# ICSSM_ICSSM_PR1_IEP0_SLV_4802E000h register map
Vendor: Texas Instruments
Peripheral module from a debugger description file (folder AM261x).
Registers are 32-bit, read-write, reset 0x0 unless marked. A register's access mark holds for its fields unless they carry their own. Offsets are as the file gives them; lines under a group give offsets from that group; [hi:lo] are bit positions; {n}, {i} and the like mark numbered series; 'fields as' and 'values as' point back to an identical list; <NAME> marks a mode.

## ICSSM_PR1_IEP0_SLV
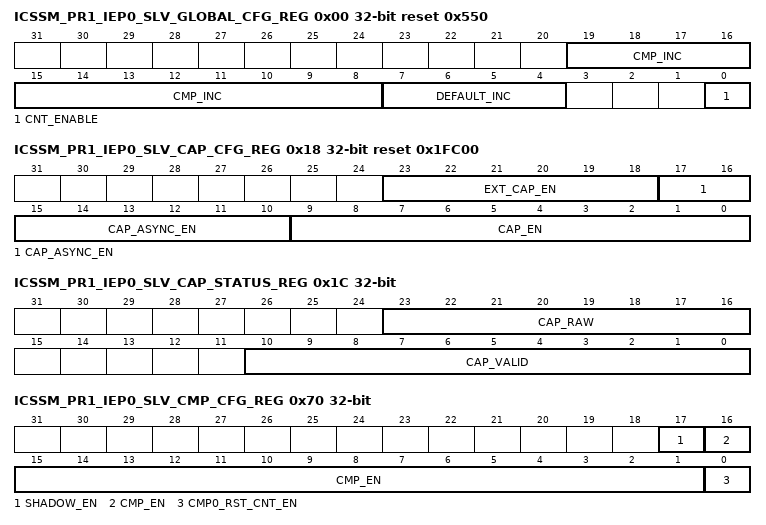
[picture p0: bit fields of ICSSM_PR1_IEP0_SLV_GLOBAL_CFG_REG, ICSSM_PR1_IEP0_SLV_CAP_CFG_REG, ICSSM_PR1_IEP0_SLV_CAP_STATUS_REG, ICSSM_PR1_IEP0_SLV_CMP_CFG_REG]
0x00 ICSSM_PR1_IEP0_SLV_GLOBAL_CFG_REG reset 0x550
  [19:8] CMP_INC, [7:4] DEFAULT_INC, [0] CNT_ENABLE
0x04 ICSSM_PR1_IEP0_SLV_GLOBAL_STATUS_REG access not given
  [0] CNT_OVF — (access R/W1TC)
0x08 ICSSM_PR1_IEP0_SLV_COMPEN_REG
  [22:0] COMPEN_CNT
0x0C ICSSM_PR1_IEP0_SLV_SLOW_COMPEN_REG
  [31:0] SLOW_COMPEN_CNT
0x10 ICSSM_PR1_IEP0_SLV_COUNT_REG0
  [31:0] COUNT_LO
0x14 ICSSM_PR1_IEP0_SLV_COUNT_REG1
  [31:0] COUNT_HI
0x18 ICSSM_PR1_IEP0_SLV_CAP_CFG_REG reset 0x1FC00
  [23:18] EXT_CAP_EN, [17:10] CAP_ASYNC_EN, [9:0] CAP_EN
0x1C ICSSM_PR1_IEP0_SLV_CAP_STATUS_REG ro
  [23:16] CAP_RAW, [10:0] CAP_VALID
{0x20+8i} ICSSM_PR1_IEP0_SLV_CAPR{i}_REG0 ro (i=0..6)
  [31:0] CAPR{i}_0
{0x24+8i} ICSSM_PR1_IEP0_SLV_CAPR{i}_REG1 ro (i=0..6)
  [31:0] CAPR{i}_1
0x58 ICSSM_PR1_IEP0_SLV_CAPF6_REG0 ro
  [31:0] CAPF6_0
0x5C ICSSM_PR1_IEP0_SLV_CAPF6_REG1 ro
  [31:0] CAPF6_1
0x60 ICSSM_PR1_IEP0_SLV_CAPR7_REG0 ro
  [31:0] CAPR7_0
0x64 ICSSM_PR1_IEP0_SLV_CAPR7_REG1 ro
  [31:0] CAPR7_1
0x68 ICSSM_PR1_IEP0_SLV_CAPF7_REG0 ro
  [31:0] CAPF7_0
0x6C ICSSM_PR1_IEP0_SLV_CAPF7_REG1 ro
  [31:0] CAPF7_1
0x70 ICSSM_PR1_IEP0_SLV_CMP_CFG_REG
  [17] SHADOW_EN, [16:1] CMP_EN, [0] CMP0_RST_CNT_EN
0x74 ICSSM_PR1_IEP0_SLV_CMP_STATUS_REG access not given
  [15:0] CMP_STATUS — (access R/W1TC)
{0x78+8i} ICSSM_PR1_IEP0_SLV_CMP{i}_REG0 (i=0..7)
  [31:0] CMP{i}_0
{0x7C+8i} ICSSM_PR1_IEP0_SLV_CMP{i}_REG1 (i=0..7)
  [31:0] CMP{i}_1
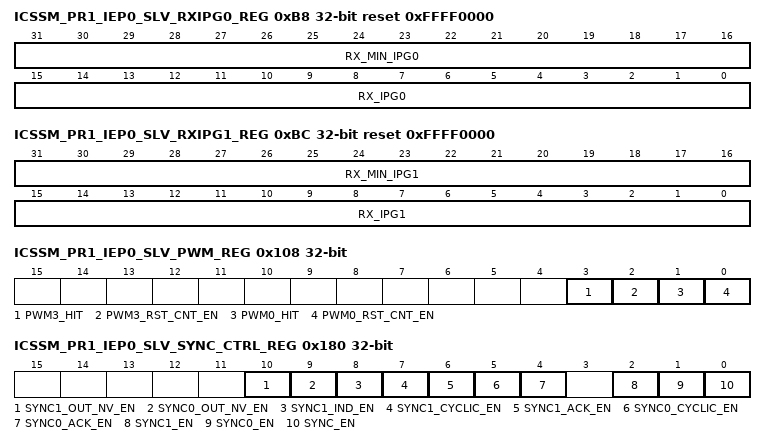
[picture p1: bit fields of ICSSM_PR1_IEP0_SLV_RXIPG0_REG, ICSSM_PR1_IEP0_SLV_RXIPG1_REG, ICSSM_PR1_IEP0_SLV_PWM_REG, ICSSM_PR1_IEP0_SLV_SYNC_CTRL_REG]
0xB8 ICSSM_PR1_IEP0_SLV_RXIPG0_REG access per field reset 0xFFFF0000
  [31:16] RX_MIN_IPG0 rw, [15:0] RX_IPG0 ro
0xBC ICSSM_PR1_IEP0_SLV_RXIPG1_REG access per field reset 0xFFFF0000
  [31:16] RX_MIN_IPG1 rw, [15:0] RX_IPG1 ro
{0x80+8i} ICSSM_PR1_IEP0_SLV_CMP{i}_REG0 (i=8..15)
  [31:0] CMP{i}_0
{0x84+8i} ICSSM_PR1_IEP0_SLV_CMP{i}_REG1 (i=8..15)
  [31:0] CMP{i}_1
0x100 ICSSM_PR1_IEP0_SLV_COUNT_RESET_VAL_REG0
  [31:0] RESET_VAL_0
0x104 ICSSM_PR1_IEP0_SLV_COUNT_RESET_VAL_REG1
  [31:0] RESET_VAL_1
0x108 ICSSM_PR1_IEP0_SLV_PWM_REG access not given
  [3] PWM3_HIT — (access R/W1TC)
  [2] PWM3_RST_CNT_EN rw
  [1] PWM0_HIT — (access R/W1TC)
  [0] PWM0_RST_CNT_EN rw
{0x10C+8i} ICSSM_PR1_IEP0_SLV_CAPR{i}_BI_REG0 ro (i=0..6)
  [31:0] CAPR{i}_0
{0x110+8i} ICSSM_PR1_IEP0_SLV_CAPR{i}_BI_REG1 ro (i=0..6)
  [31:0] CAPR{i}_1
0x144 ICSSM_PR1_IEP0_SLV_CAPF6_BI_REG0 ro
  [31:0] CAPF6_0
0x148 ICSSM_PR1_IEP0_SLV_CAPF6_BI_REG1 ro
  [31:0] CAPF6_1
0x14C ICSSM_PR1_IEP0_SLV_CAPR7_BI_REG0 ro
  [31:0] CAPR7_0
0x150 ICSSM_PR1_IEP0_SLV_CAPR7_BI_REG1 ro
  [31:0] CAPR7_1
0x154 ICSSM_PR1_IEP0_SLV_CAPF7_BI_REG0 ro
  [31:0] CAPF7_0
0x158 ICSSM_PR1_IEP0_SLV_CAPF7_BI_REG1 ro
  [31:0] CAPF7_1
0x180 ICSSM_PR1_IEP0_SLV_SYNC_CTRL_REG
  [10] SYNC1_OUT_NV_EN, [9] SYNC0_OUT_NV_EN, [8] SYNC1_IND_EN, [7] SYNC1_CYCLIC_EN, [6] SYNC1_ACK_EN, [5] SYNC0_CYCLIC_EN, [4] SYNC0_ACK_EN, [2] SYNC1_EN, [1] SYNC0_EN, [0] SYNC_EN
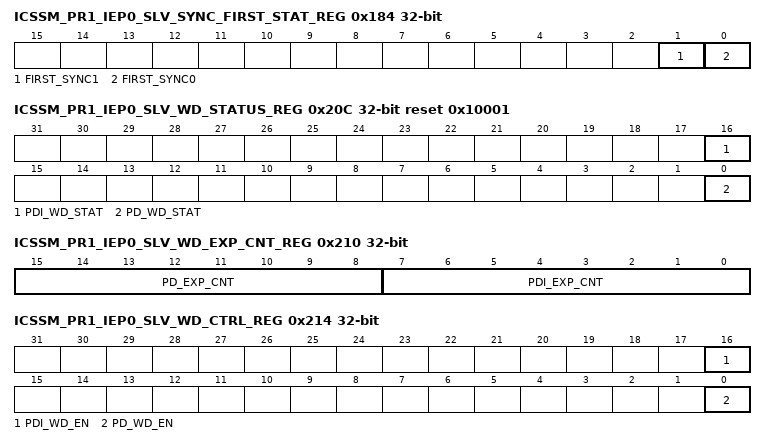
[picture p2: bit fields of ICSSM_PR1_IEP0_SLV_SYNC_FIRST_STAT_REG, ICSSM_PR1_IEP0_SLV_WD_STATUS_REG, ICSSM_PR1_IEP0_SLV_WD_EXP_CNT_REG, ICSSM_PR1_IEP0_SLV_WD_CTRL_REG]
0x184 ICSSM_PR1_IEP0_SLV_SYNC_FIRST_STAT_REG ro
  [1] FIRST_SYNC1, [0] FIRST_SYNC0
0x188 ICSSM_PR1_IEP0_SLV_SYNC0_STAT_REG ro
  [0] SYNC0_PEND
0x18C ICSSM_PR1_IEP0_SLV_SYNC1_STAT_REG ro
  [0] SYNC1_PEND
0x190 ICSSM_PR1_IEP0_SLV_SYNC_PWIDTH_REG
  [31:0] SYNC_HPW
0x194 ICSSM_PR1_IEP0_SLV_SYNC0_PERIOD_REG reset 0x1
  [31:0] SYNC0_PERIOD
0x198 ICSSM_PR1_IEP0_SLV_SYNC1_DELAY_REG
  [31:0] SYNC1_DELAY
0x19C ICSSM_PR1_IEP0_SLV_SYNC_START_REG
  [31:0] SYNC_START
0x200 ICSSM_PR1_IEP0_SLV_WD_PREDIV_REG reset 0x4E20
  [15:0] PRE_DIV
0x204 ICSSM_PR1_IEP0_SLV_PDI_WD_TIM_REG reset 0x3E8
  [15:0] PDI_WD_TIME
0x208 ICSSM_PR1_IEP0_SLV_PD_WD_TIM_REG reset 0x3E8
  [15:0] PD_WD_TIME
0x20C ICSSM_PR1_IEP0_SLV_WD_STATUS_REG ro reset 0x10001
  [16] PDI_WD_STAT, [0] PD_WD_STAT
0x210 ICSSM_PR1_IEP0_SLV_WD_EXP_CNT_REG
  [15:8] PD_EXP_CNT, [7:0] PDI_EXP_CNT
0x214 ICSSM_PR1_IEP0_SLV_WD_CTRL_REG
  [16] PDI_WD_EN, [0] PD_WD_EN
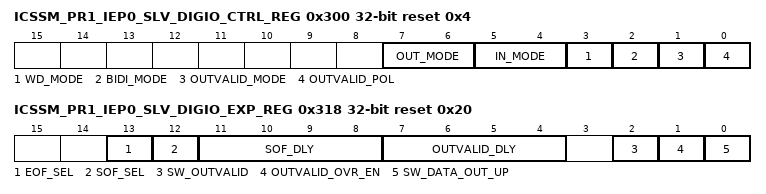
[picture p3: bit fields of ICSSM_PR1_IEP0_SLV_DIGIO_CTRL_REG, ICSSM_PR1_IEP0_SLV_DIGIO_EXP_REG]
0x300 ICSSM_PR1_IEP0_SLV_DIGIO_CTRL_REG access per field reset 0x4
  [7:6] OUT_MODE rw, [5:4] IN_MODE rw, [3] WD_MODE rw, [2] BIDI_MODE ro, [1] OUTVALID_MODE rw, [0] OUTVALID_POL ro
0x304 ICSSM_PR1_IEP0_SLV_DIGIO_STATUS_REG ro
  [31:0] DIGIO_STAT
0x308 ICSSM_PR1_IEP0_SLV_DIGIO_DATA_IN_REG ro
  [31:0] DATA_IN
0x30C ICSSM_PR1_IEP0_SLV_DIGIO_DATA_IN_RAW_REG ro
  [31:0] DATA_IN_RAW
0x310 ICSSM_PR1_IEP0_SLV_DIGIO_DATA_OUT_REG
  [31:0] DATA_OUT
0x314 ICSSM_PR1_IEP0_SLV_DIGIO_DATA_OUT_EN_REG
  [31:0] DATA_OUT_EN
0x318 ICSSM_PR1_IEP0_SLV_DIGIO_EXP_REG reset 0x20
  [13] EOF_SEL, [12] SOF_SEL, [11:8] SOF_DLY, [7:4] OUTVALID_DLY, [2] SW_OUTVALID, [1] OUTVALID_OVR_EN, [0] SW_DATA_OUT_UP
